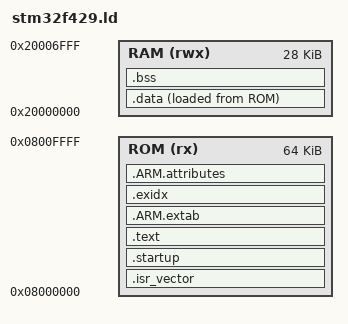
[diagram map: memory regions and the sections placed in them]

/*
 Copyright Christopher Kormanyos 2007 - 2022.
 Distributed under the Boost Software License,
 Version 1.0. (See accompanying file LICENSE_1_0.txt
 or copy at http://www.boost.org/LICENSE_1_0.txt)
*/

/* Linker script for STM32F4xx ARM(R) Cortex(TM)-M4 MCU */

ENTRY(__my_startup)

INPUT(libc.a libm.a libgcc.a)

OUTPUT_FORMAT("elf32-littlearm", "elf32-littlearm", "elf32-littlearm")
OUTPUT_ARCH(arm)

/* The beginning and end of the program ROM area */
/* Set up a ROM area with a size of 64K */
_rom_begin = 0x08000000;
_rom_end   = 0x08010000;

/* The beginning and end (i.e., the top) of the stack */
/* Set up a stack with a size of 4K */
_stack_begin = 0x20007000;
_stack_end   = 0x20008000;

__initial_stack_pointer = 0x20008000 - 4;

MEMORY
{
  ROM(rx)  : ORIGIN = 0x08000000, LENGTH = 64K
  RAM(rwx) : ORIGIN = 0x20000000, LENGTH = 0x7000
}

SECTIONS
{
  . = 0x08000000;
  . = ALIGN(4);

  /* ISR vectors */
  .isr_vector :
  {
    *(.isr_vector)
    . = ALIGN(0x10);
    KEEP(*(.isr_vector))
  } > ROM = 0xAAAA

  /* startup */
  .startup :
  {
    *(.startup)
    . = ALIGN(0x10);
    KEEP(*(.startup))
  } > ROM = 0x5555

  /* Program code (text), read-only data and static ctors */
  .text :
  {
    _ctors_begin = .;
    KEEP(*(SORT(.init_array.*)))
    KEEP(*(.init_array*))
    _ctors_end = .;
    *(.progmem*)
    . = ALIGN(4);
    *(.text)
    . = ALIGN(4);
    *(.text*)
    . = ALIGN(4);
    *(.rodata)
    . = ALIGN(4);
    *(.rodata*)
    . = ALIGN(4);
    *(.glue_7)
    . = ALIGN(4);
    *(.glue_7t)
    . = ALIGN(4);
  } > ROM

  .ARM.extab :
  {
    . = ALIGN(4);
    *(.ARM.extab)
    *(.gnu.linkonce.armextab.*)
    . = ALIGN(4);
  } > ROM

  .exidx :
  {
    . = ALIGN(4);
    PROVIDE(__exidx_start = .);
    *(.ARM.exidx*)
    . = ALIGN(4);
    PROVIDE(__exidx_end = .);
  } > ROM

  .ARM.attributes :
  {
    *(.ARM.attributes)
  } > ROM

  . = 0x20000000;
  . = ALIGN(4);

  /* The ROM-to-RAM initialized data section */
  .data :
  {
    _data_begin = .;
    *(.data)
    . = ALIGN(4);
    KEEP (*(.data))
    *(.data*)
    . = ALIGN(4);
    KEEP (*(.data*))
    _data_end = .;
  } > RAM AT > ROM

  /* The uninitialized (zero-cleared) data section */
  .bss :
  {
    _bss_begin = .;
    *(.bss)
    . = ALIGN(4);
    KEEP (*(.bss))
    *(.bss*)
    . = ALIGN(4);
    KEEP (*(.bss*))
    _bss_end = .;
  } > RAM

  PROVIDE(end = .);
  PROVIDE(_fini = .);

  _rom_data_begin = LOADADDR(.data);
}
